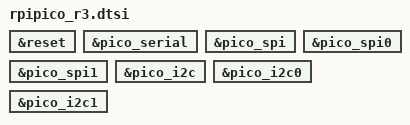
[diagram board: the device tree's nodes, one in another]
/*
 * Copyright (c) 2023 TiaC Systems
 * SPDX-License-Identifier: Apache-2.0
 */

#include <freq.h>

#include "rpipico_r3_connector.dtsi"
#include "rpipico_r3-pinctrl.dtsi"
#include "rpipico_r3-spi0.dtsi"
#include "rpipico_r3-spi1.dtsi"

&reset {
	status = "okay";
};

rpipico_serial: &pico_serial {};

rpipico_spi: &pico_spi {};
rpipico_spi0: &pico_spi0 {};
rpipico_spi1: &pico_spi1 {};

rpipico_i2c: &pico_i2c {};
rpipico_i2c0: &pico_i2c0 {};
rpipico_i2c1: &pico_i2c1 {};

#include "rpipico_r3-tweaks.dtsi"
